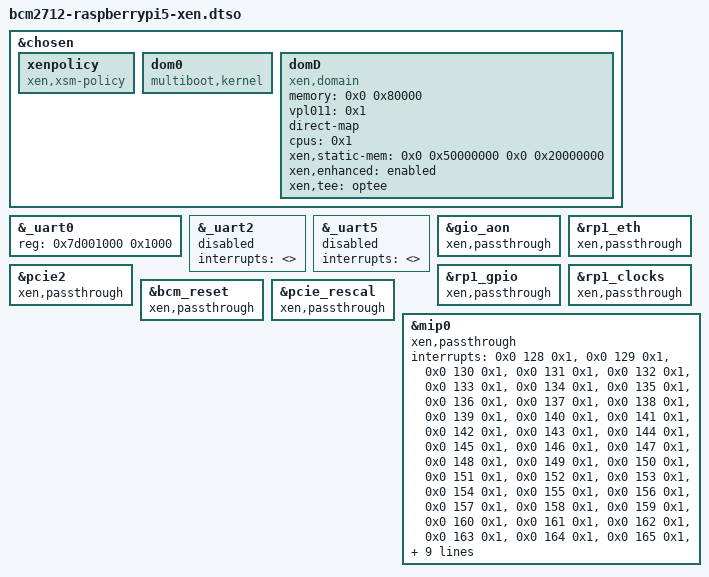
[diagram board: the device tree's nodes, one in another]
/*
 * Copyright (c) 2024 EPAM systems
 *
 * SPDX-License-Identifier: Apache-2.0
*/
/dts-v1/;
/plugin/;

&chosen {
	#address-cells = <0x2>;
	#size-cells = <0x2>;
	xenpolicy {
		compatible = "xen,xsm-policy", "multiboot-module";
	};
	dom0 {
		compatible = "multiboot,kernel", "multiboot,module";
	};
	domD {
		compatible = "xen,domain";
		#address-cells = <0x2>;
		#size-cells = <0x2>;
		memory = <0x0 0x80000>;
		vpl011 = <0x1>;
		direct-map;
		cpus = <0x1>;
		xen,static-mem = <0x0 0x50000000 0x0 0x20000000>;
		xen,enhanced = "enabled";
		xen,tee = "optee";
	};
};

/*
 * HACK uart regs to be xen page aligned to avoid XEN fail in dom0less mode
 * when vuart "vpl011" is used for DomU
 */
&_uart0 {
	reg = <0x7d001000 0x1000>;
};

/*
 * HACK there is number of uarts use same IRQ, so XEN fails when uses
 * _uart0 as console uart.
 * Delete interrupts info and disable devices;
 */
&_uart2 {
	interrupts = <>;
	status = "disabled";
};
&_uart5 {
	interrupts = <>;
	status = "disabled";
};

&gio_aon        { xen,passthrough; };
&rp1_eth        { xen,passthrough; };
&pcie2          { xen,passthrough; };
&rp1_gpio       { xen,passthrough; };
&rp1_clocks     { xen,passthrough; };
&bcm_reset      { xen,passthrough; };
&pcie_rescal    { xen,passthrough; };
&mip0           { xen,passthrough; };

&mip0 {
			interrupts =
			<0x0 128 0x1>,
			<0x0 129 0x1>,
			<0x0 130 0x1>,
			<0x0 131 0x1>,
			<0x0 132 0x1>,
			<0x0 133 0x1>,
			<0x0 134 0x1>,
			<0x0 135 0x1>,
			<0x0 136 0x1>,
			<0x0 137 0x1>,
			<0x0 138 0x1>,
			<0x0 139 0x1>,
			<0x0 140 0x1>,
			<0x0 141 0x1>,
			<0x0 142 0x1>,
			<0x0 143 0x1>,

			<0x0 144 0x1>,
			<0x0 145 0x1>,
			<0x0 146 0x1>,
			<0x0 147 0x1>,
			<0x0 148 0x1>,
			<0x0 149 0x1>,
			<0x0 150 0x1>,
			<0x0 151 0x1>,
			<0x0 152 0x1>,
			<0x0 153 0x1>,
			<0x0 154 0x1>,
			<0x0 155 0x1>,
			<0x0 156 0x1>,
			<0x0 157 0x1>,
			<0x0 158 0x1>,
			<0x0 159 0x1>,

			<0x0 160 0x1>,
			<0x0 161 0x1>,
			<0x0 162 0x1>,
			<0x0 163 0x1>,
			<0x0 164 0x1>,
			<0x0 165 0x1>,
			<0x0 166 0x1>,
			<0x0 167 0x1>,
			<0x0 168 0x1>,
			<0x0 169 0x1>,
			<0x0 170 0x1>,
			<0x0 171 0x1>,
			<0x0 172 0x1>,
			<0x0 173 0x1>,
			<0x0 174 0x1>,
			<0x0 175 0x1>,

			<0x0 176 0x1>,
			<0x0 177 0x1>,
			<0x0 178 0x1>,
			<0x0 179 0x1>,
			<0x0 180 0x1>,
			<0x0 181 0x1>,
			<0x0 182 0x1>,
			<0x0 183 0x1>,
			<0x0 184 0x1>,
			<0x0 185 0x1>,
			<0x0 186 0x1>,
			<0x0 187 0x1>,
			<0x0 188 0x1>,
			<0x0 189 0x1>,
			<0x0 190 0x1>,
			<0x0 191 0x1>
			;
};
